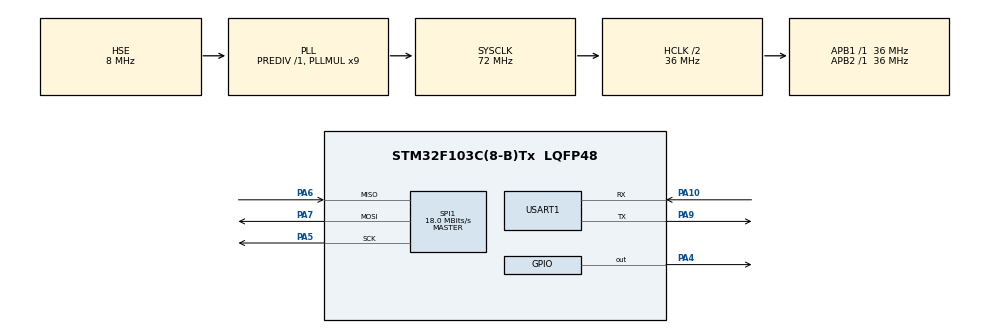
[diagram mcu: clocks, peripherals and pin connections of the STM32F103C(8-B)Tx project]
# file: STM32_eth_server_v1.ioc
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Mcu.Family=STM32F1
Mcu.Name=STM32F103C(8-B)Tx
Mcu.Package=LQFP48
NVIC.PriorityGroup=NVIC_PRIORITYGROUP_4
PA10.Mode=Asynchronous
PA10.Signal=USART1_RX
PA13.Mode=Serial_Wire
PA13.Signal=SYS_JTMS-SWDIO
PA14.Mode=Serial_Wire
PA14.Signal=SYS_JTCK-SWCLK
PA4.Signal=GPIO_Output
PA5.Mode=Full_Duplex_Master
PA5.Signal=SPI1_SCK
PA6.Mode=Full_Duplex_Master
PA6.Signal=SPI1_MISO
PA7.Mode=Full_Duplex_Master
PA7.Signal=SPI1_MOSI
PA9.Mode=Asynchronous
PA9.Signal=USART1_TX
PD0-OSC_IN.Mode=HSE-External-Oscillator
PD0-OSC_IN.Signal=RCC_OSC_IN
PD1-OSC_OUT.Mode=HSE-External-Oscillator
PD1-OSC_OUT.Signal=RCC_OSC_OUT
ProjectManager.HeapSize=0x200
ProjectManager.StackSize=0x400
ProjectManager.TargetToolchain=STM32CubeIDE
RCC.AHBCLKDivider=RCC_SYSCLK_DIV2
RCC.AHBFreq_Value=36000000
RCC.APB1Freq_Value=36000000
RCC.APB1TimFreq_Value=36000000
RCC.APB2Freq_Value=36000000
RCC.APB2TimFreq_Value=36000000
RCC.HCLKFreq_Value=36000000
RCC.PLLMUL=RCC_PLL_MUL9
RCC.PLLSourceVirtual=RCC_PLLSOURCE_HSE
RCC.SYSCLKFreq_VALUE=72000000
RCC.SYSCLKSource=RCC_SYSCLKSOURCE_PLLCLK
RCC.USBFreq_Value=72000000
SPI1.BaudRatePrescaler=SPI_BAUDRATEPRESCALER_2
SPI1.CalculateBaudRate=18.0 MBits/s
SPI1.Direction=SPI_DIRECTION_2LINES
SPI1.Mode=SPI_MODE_MASTER
SPI1.VirtualType=VM_MASTER
USART1.VirtualMode=VM_ASYNC
board=custom

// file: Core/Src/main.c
/* USER CODE BEGIN Header */
/**
  ******************************************************************************
  * @file           : main.c
  * @brief          : Main program body
  ******************************************************************************
  * @attention
  *
  * <h2><center>&copy; Copyright (c) 2020 STMicroelectronics.
  * All rights reserved.</center></h2>
  *
  * This software component is licensed by ST under BSD 3-Clause license,
  * the "License"; You may not use this file except in compliance with the
  * License. You may obtain a copy of the License at:
  *                        opensource.org/licenses/BSD-3-Clause
  *
  ******************************************************************************
  */
/* USER CODE END Header */

#include "main.h"

/* USER CODE BEGIN PM */

#define SEPARATOR            "=============================================\r\n"
#define WELCOME_MSG  		 "Welcome to STM32Nucleo Ethernet configuration\r\n"
#define NETWORK_MSG  		 "Network configuration:\r\n"
#define IP_MSG 		 		 "  IP ADDRESS:  %d.%d.%d.%d\r\n"
#define NETMASK_MSG	         "  NETMASK:     %d.%d.%d.%d\r\n"
#define GW_MSG 		 		 "  GATEWAY:     %d.%d.%d.%d\r\n"
#define MAC_MSG		 		 "  MAC ADDRESS: %x:%x:%x:%x:%x:%x\r\n"
#define GREETING_MSG 		 "Well done guys! Welcome to the IoT world. Bye!\r\n"
#define CONN_ESTABLISHED_MSG "Connection established with remote IP: %d.%d.%d.%d:%d\r\n"
#define SENT_MESSAGE_MSG	 "Sent a message. Let's close the socket!\r\n"
#define WRONG_RETVAL_MSG	 "Something went wrong; return value: %d\r\n"
#define WRONG_STATUS_MSG	 "Something went wrong; STATUS: %d\r\n"
#define LISTEN_ERR_MSG		 "LISTEN Error!\r\n"

#define TCP_PORT 5001

#define PRINT_STR(msg) do  {										\
  HAL_UART_Transmit(&huart1, (uint8_t*)msg, strlen(msg), 100);		\
} while(0)

#define PRINT_HEADER() do  {													\
  HAL_UART_Transmit(&huart1, (uint8_t*)SEPARATOR, strlen(SEPARATOR), 100);		\
  HAL_UART_Transmit(&huart1, (uint8_t*)WELCOME_MSG, strlen(WELCOME_MSG), 100);	\
  HAL_UART_Transmit(&huart1, (uint8_t*)SEPARATOR, strlen(SEPARATOR), 100);		\
} while(0)

#define PRINT_NETINFO(netInfo) do { 																					\
  HAL_UART_Transmit(&huart1, (uint8_t*)NETWORK_MSG, strlen(NETWORK_MSG), 100);											\
  sprintf(msg, MAC_MSG, netInfo.mac[0], netInfo.mac[1], netInfo.mac[2], netInfo.mac[3], netInfo.mac[4], netInfo.mac[5]);\
  HAL_UART_Transmit(&huart1, (uint8_t*)msg, strlen(msg), 100);															\
  sprintf(msg, IP_MSG, netInfo.ip[0], netInfo.ip[1], netInfo.ip[2], netInfo.ip[3]);										\
  HAL_UART_Transmit(&huart1, (uint8_t*)msg, strlen(msg), 100);															\
  sprintf(msg, NETMASK_MSG, netInfo.sn[0], netInfo.sn[1], netInfo.sn[2], netInfo.sn[3]);								\
  HAL_UART_Transmit(&huart1, (uint8_t*)msg, strlen(msg), 100);															\
  sprintf(msg, GW_MSG, netInfo.gw[0], netInfo.gw[1], netInfo.gw[2], netInfo.gw[3]);										\
  HAL_UART_Transmit(&huart1, (uint8_t*)msg, strlen(msg), 100);															\
} while(0)

/* USER CODE END PM */

SPI_HandleTypeDef hspi1;

UART_HandleTypeDef huart1;

char msg[60];

void SystemClock_Config(void);
static void MX_GPIO_Init(void);
static void MX_SPI1_Init(void);
static void MX_USART1_UART_Init(void);

/* USER CODE BEGIN 0 */

void cs_sel() {
	HAL_GPIO_WritePin(GPIOA, GPIO_PIN_4, GPIO_PIN_RESET); //CS LOW
}

void cs_desel() {
	HAL_GPIO_WritePin(GPIOA, GPIO_PIN_4, GPIO_PIN_SET); //CS HIGH
}

uint8_t spi_rb(void) {
	uint8_t rbuf;
	HAL_SPI_Receive(&hspi1, &rbuf, 1, 0xFFFFFFFF);
	return rbuf;
}

void spi_wb(uint8_t b) {
	HAL_SPI_Transmit(&hspi1, &b, 1, 0xFFFFFFFF);
}

void SwitchLED(){
	HAL_GPIO_TogglePin(GPIOC, GPIO_PIN_13);
}

/* USER CODE END 0 */

int main(void)
{
  /* USER CODE BEGIN 1 */

	uint8_t retVal, sockStatus;
	int16_t rcvLen;
	uint8_t rcvBuf[20], bufSize[] = {2, 2, 2, 2, 2, 2, 2, 2};

  /* USER CODE END 1 */

  /* MCU Configuration--------------------------------------------------------*/

  /* Reset of all peripherals, Initializes the Flash interface and the Systick. */
  HAL_Init();

  /* Configure the system clock */
  SystemClock_Config();

  /* Initialize all configured peripherals */
  MX_GPIO_Init();
  MX_SPI1_Init();
  MX_USART1_UART_Init();

  /* USER CODE BEGIN 2 */

  PRINT_HEADER();

  reg_wizchip_cs_cbfunc(cs_sel, cs_desel);
  reg_wizchip_spi_cbfunc(spi_rb, spi_wb);
  wizchip_init(bufSize, bufSize);
  wiz_NetInfo netInfo = { .mac		= {0x00, 0x08, 0xdc, 0xab, 0xee}, //Mac Addres f -> e
						  .ip 		= {192, 168, 2, 192},
						  .sn		= {255, 255, 255, 0},
						  .gw		= {192, 168, 2, 1} };
  wizchip_setnetinfo(&netInfo);
  wizchip_getnetinfo(&netInfo);
  PRINT_NETINFO(netInfo);

  reconnect:
  /* Open socket 0 as TCP_SOCKET with port TCP_PORT = 5001 */
     if((retVal = socket(0, Sn_MR_TCP, TCP_PORT, SF_TCP_NODELAY)) == 0) {
   	  /* Put socket in LISTEN mode. This means we are creating a TCP server */
   	  if((retVal = listen(0)) == SOCK_OK) {
   		  /* While socket is in LISTEN mode we wait for a remote connection */
   		  while((sockStatus = getSn_SR(0)) == SOCK_LISTEN)
   			  HAL_Delay(800);
   		  /* OK. Got a remote peer. Let's send a message to it */
   		  while(1) {
   			  /* If connection is ESTABLISHED with remote peer */
   			  if((sockStatus = getSn_SR(0)) == SOCK_ESTABLISHED) {
//   				  HAL_Delay(1000);
   				  uint8_t remoteIP[4];
   				  uint16_t remotePort;
   				  /* Retrieving remote peer IP and port number */
   				  getsockopt(0, SO_DESTIP, remoteIP);
   				  getsockopt(0,SO_DESTPORT, (uint8_t*)&remotePort);
   				  sprintf(msg, CONN_ESTABLISHED_MSG, remoteIP[0], remoteIP[1], remoteIP[2], remoteIP[3], remotePort);
   				  PRINT_STR(msg);
   				  /* Let's send a welcome message and closing socket */
  				  if((retVal = send(0, GREETING_MSG, strlen(GREETING_MSG))) == (int16_t)strlen(GREETING_MSG))
//   				  if(retVal = recv(0,&rcvBuf, strlen(rcvBuf)) = (int8_t)strlen(rcvBuf)){

  					  // if (Sn_SR == SOCK_CLOSE_WAIT) //PROBAR CODIGO
  				  PRINT_STR(SENT_MESSAGE_MSG);
   				  else { /* Ops: something went wrong during data transfer */
   					  sprintf(msg, WRONG_RETVAL_MSG, retVal);
   					  PRINT_STR(msg);
   				  }
  				  while((sockStatus = getSn_SR(0)) !=  SOCK_CLOSE_WAIT){

  					  HAL_Delay(800);

  				  }

   				  break;
   			  }
   			  else { /* Something went wrong with remote peer, maybe the connection was closed unexpectedly */
   				  sprintf(msg, WRONG_STATUS_MSG, sockStatus);
   				  PRINT_STR(msg);
   				  break;
   			  }
   		  }

   	  } else /* Ops: socket not in LISTEN mode. Something went wrong */
   		  PRINT_STR(LISTEN_ERR_MSG);
     } else { /* Can't open the socket. This means something is wrong with W5100 configuration: maybe SPI issue? */
   	  sprintf(msg, WRONG_RETVAL_MSG, retVal);
   	  PRINT_STR(msg);
     }

     /* We close the socket and start a connection again */
     disconnect(0);
     close(0);
     goto reconnect;

  /* USER CODE END 2 */

  /* Infinite loop */
  while (1)
  {

  }
}

void SystemClock_Config(void)
{
  RCC_OscInitTypeDef RCC_OscInitStruct = {0};
  RCC_ClkInitTypeDef RCC_ClkInitStruct = {0};

  /** Initializes the CPU, AHB and APB busses clocks
  */
  RCC_OscInitStruct.OscillatorType = RCC_OSCILLATORTYPE_HSE;
  RCC_OscInitStruct.HSEState = RCC_HSE_ON;
  RCC_OscInitStruct.HSEPredivValue = RCC_HSE_PREDIV_DIV1;
  RCC_OscInitStruct.HSIState = RCC_HSI_ON;
  RCC_OscInitStruct.PLL.PLLState = RCC_PLL_ON;
  RCC_OscInitStruct.PLL.PLLSource = RCC_PLLSOURCE_HSE;
  RCC_OscInitStruct.PLL.PLLMUL = RCC_PLL_MUL9;
  if (HAL_RCC_OscConfig(&RCC_OscInitStruct) != HAL_OK)
  {
    Error_Handler();
  }
  /** Initializes the CPU, AHB and APB busses clocks
  */
  RCC_ClkInitStruct.ClockType = RCC_CLOCKTYPE_HCLK|RCC_CLOCKTYPE_SYSCLK
                              |RCC_CLOCKTYPE_PCLK1|RCC_CLOCKTYPE_PCLK2;
  RCC_ClkInitStruct.SYSCLKSource = RCC_SYSCLKSOURCE_PLLCLK;
  RCC_ClkInitStruct.AHBCLKDivider = RCC_SYSCLK_DIV2;
  RCC_ClkInitStruct.APB1CLKDivider = RCC_HCLK_DIV1;
  RCC_ClkInitStruct.APB2CLKDivider = RCC_HCLK_DIV1;

  if (HAL_RCC_ClockConfig(&RCC_ClkInitStruct, FLASH_LATENCY_2) != HAL_OK)
  {
    Error_Handler();
  }
}

static void MX_SPI1_Init(void)
{

  /* SPI1 parameter configuration*/
  hspi1.Instance = SPI1;
  hspi1.Init.Mode = SPI_MODE_MASTER;
  hspi1.Init.Direction = SPI_DIRECTION_2LINES;
  hspi1.Init.DataSize = SPI_DATASIZE_8BIT;
  hspi1.Init.CLKPolarity = SPI_POLARITY_LOW;
  hspi1.Init.CLKPhase = SPI_PHASE_1EDGE;
  hspi1.Init.NSS = SPI_NSS_SOFT;
  hspi1.Init.BaudRatePrescaler = SPI_BAUDRATEPRESCALER_4;
  hspi1.Init.FirstBit = SPI_FIRSTBIT_MSB;
  hspi1.Init.TIMode = SPI_TIMODE_DISABLE;
  hspi1.Init.CRCCalculation = SPI_CRCCALCULATION_DISABLE;
  hspi1.Init.CRCPolynomial = 10;
  if (HAL_SPI_Init(&hspi1) != HAL_OK)
  {
    Error_Handler();
  }

}

static void MX_USART1_UART_Init(void)
{

  huart1.Instance = USART1;
  huart1.Init.BaudRate = 115200;
  huart1.Init.WordLength = UART_WORDLENGTH_8B;
  huart1.Init.StopBits = UART_STOPBITS_1;
  huart1.Init.Parity = UART_PARITY_NONE;
  huart1.Init.Mode = UART_MODE_TX_RX;
  huart1.Init.HwFlowCtl = UART_HWCONTROL_NONE;
  huart1.Init.OverSampling = UART_OVERSAMPLING_16;
  if (HAL_UART_Init(&huart1) != HAL_OK)
  {
    Error_Handler();
  }

}

static void MX_GPIO_Init(void)
{
  GPIO_InitTypeDef GPIO_InitStruct = {0};

  /* GPIO Ports Clock Enable */
  __HAL_RCC_GPIOD_CLK_ENABLE();
  __HAL_RCC_GPIOA_CLK_ENABLE();
  __HAL_RCC_GPIOC_CLK_ENABLE();		//Inicializo clk en puerto GPIOC

  /*Configure GPIO pin Output Level */
  HAL_GPIO_WritePin(GPIOC, GPIO_PIN_13, GPIO_PIN_RESET);

  /*Configure GPIO pin Output Level */
  HAL_GPIO_WritePin(GPIOA, GPIO_PIN_4, GPIO_PIN_RESET);

  /*Configure GPIO pin : PC13 */
  GPIO_InitStruct.Pin = GPIO_PIN_13;
  GPIO_InitStruct.Mode = GPIO_MODE_OUTPUT_PP;
  GPIO_InitStruct.Pull = GPIO_NOPULL;
  GPIO_InitStruct.Speed = GPIO_SPEED_FREQ_LOW;
  HAL_GPIO_Init(GPIOC, &GPIO_InitStruct);

  /*Configure GPIO pin : PA4 */
  GPIO_InitStruct.Pin = GPIO_PIN_4;
  GPIO_InitStruct.Mode = GPIO_MODE_OUTPUT_PP;
  GPIO_InitStruct.Pull = GPIO_PULLUP;	//GPIO_NOPULL
  GPIO_InitStruct.Speed = GPIO_SPEED_FREQ_LOW;
  HAL_GPIO_Init(GPIOA, &GPIO_InitStruct);

}

void Error_Handler(void)
{
}

/************************ (C) COPYRIGHT STMicroelectronics *****END OF FILE****/
